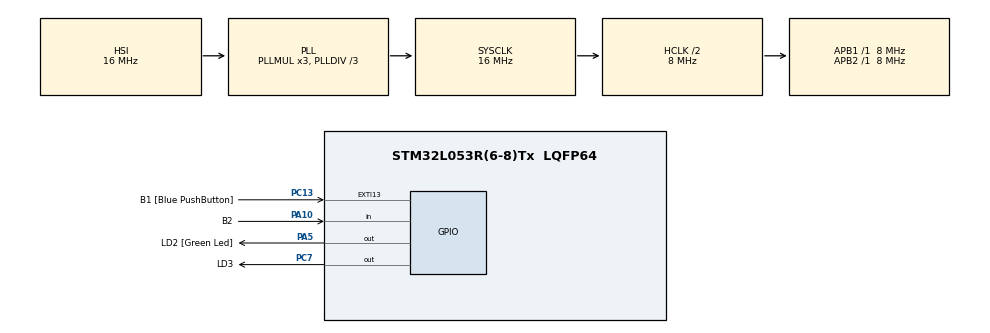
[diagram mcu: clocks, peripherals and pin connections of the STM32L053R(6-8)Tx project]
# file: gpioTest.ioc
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Mcu.Family=STM32L0
Mcu.Name=STM32L053R(6-8)Tx
Mcu.Package=LQFP64
NVIC.EXTI4_15_IRQn=true\:0\:0\:false\:false\:true\:true\:true
NVIC.TIM2_IRQn=true\:0\:0\:false\:false\:true\:true\:true
PA10.GPIO_Label=B2
PA10.Signal=GPIO_Input
PA13.GPIO_Label=TMS
PA13.Signal=SYS_SWDIO
PA14.GPIO_Label=TCK
PA14.Signal=SYS_SWCLK
PA2.GPIO_Label=USART_TX
PA2.Signal=USART2_TX
PA3.GPIO_Label=USART_RX
PA3.Signal=USART2_RX
PA5.GPIO_Label=LD2 [Green Led]
PA5.Signal=GPIO_Output
PC13.GPIO_Label=B1 [Blue PushButton]
PC13.GPIO_ModeDefaultEXTI=GPIO_MODE_IT_FALLING
PC13.Signal=GPXTI13
PC14-OSC32_IN.Signal=RCC_OSC32_IN
PC15-OSC32_OUT.Signal=RCC_OSC32_OUT
PC7.GPIO_Label=LD3
PC7.Signal=GPIO_Output
PH0-OSC_IN.Mode=HSE-External-Oscillator
PH0-OSC_IN.Signal=RCC_OSC_IN
PH1-OSC_OUT.Mode=HSE-External-Oscillator
PH1-OSC_OUT.Signal=RCC_OSC_OUT
ProjectManager.HeapSize=0x200
ProjectManager.StackSize=0x400
ProjectManager.TargetToolchain=MDK-ARM V5
RCC.AHBCLKDivider=RCC_SYSCLK_DIV2
RCC.AHBFreq_Value=8000000
RCC.APB1Freq_Value=8000000
RCC.APB1TimFreq_Value=8000000
RCC.APB2Freq_Value=8000000
RCC.APB2TimFreq_Value=8000000
RCC.HCLKFreq_Value=8000000
RCC.HSE_VALUE=8000000
RCC.HSI16_VALUE=16000000
RCC.HSI48_VALUE=48000000
RCC.HSI_VALUE=16000000
RCC.LSEState=RCC_LSE_ON
RCC.LSE_VALUE=32768
RCC.MSI_VALUE=2097000
RCC.PLLDIV=RCC_PLLDIV_3
RCC.SYSCLKFreq_VALUE=16000000
RCC.SYSCLKSource=RCC_SYSCLKSOURCE_PLLCLK
RCC.VCOOutputFreq_Value=48000000
TIM2.Period=800
TIM2.Prescaler=3999
VP_TIM2_VS_ClockSourceINT.Mode=Internal
board=NUCLEO-L053R8

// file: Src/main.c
/* USER CODE BEGIN Header */
/**
  ******************************************************************************
  * @file           : main.c
  * @brief          : Main program body
  ******************************************************************************
  * @attention
  *
  * <h2><center>&copy; Copyright (c) 2019 STMicroelectronics.
  * All rights reserved.</center></h2>
  *
  * This software component is licensed by ST under BSD 3-Clause license,
  * the "License"; You may not use this file except in compliance with the
  * License. You may obtain a copy of the License at:
  *                        opensource.org/licenses/BSD-3-Clause
  *
  ******************************************************************************
  */
/* USER CODE END Header */

#include "main.h"

TIM_HandleTypeDef htim2;

void SystemClock_Config(void);
static void MX_GPIO_Init(void);
static void MX_TIM2_Init(void);

int main(void)
{

  /* MCU Configuration--------------------------------------------------------*/

  /* Reset of all peripherals, Initializes the Flash interface and the Systick. */
  HAL_Init();

  /* Configure the system clock */
  SystemClock_Config();

  /* Initialize all configured peripherals */
  MX_GPIO_Init();
  MX_TIM2_Init();
  /* USER CODE BEGIN 2 */
	// start the timer2
	HAL_TIM_Base_Start_IT(&htim2);
  /* USER CODE END 2 */

  /* Infinite loop */
  /* USER CODE BEGIN WHILE */
  while (1)
  {
    ;
    /* USER CODE END WHILE */

    /* USER CODE BEGIN 3 */
		//HAL_GPIO_TogglePin(LD2_GPIO_Port, LD2_Pin);
		//HAL_Delay(1000);
		//if(HAL_GPIO_ReadPin(B1_GPIO_Port, B1_Pin))
			//HAL_GPIO_WritePin(LD2_GPIO_Port, LD2_Pin, GPIO_PIN_SET);
		//else
 			//HAL_GPIO_WritePin(LD2_GPIO_Port, LD2_Pin, GPIO_PIN_RESET);
  }
  /* USER CODE END 3 */
}

void SystemClock_Config(void)
{
  RCC_OscInitTypeDef RCC_OscInitStruct = {0};
  RCC_ClkInitTypeDef RCC_ClkInitStruct = {0};

  /** Configure the main internal regulator output voltage
  */
  __HAL_PWR_VOLTAGESCALING_CONFIG(PWR_REGULATOR_VOLTAGE_SCALE1);
  /** Initializes the CPU, AHB and APB busses clocks
  */
  RCC_OscInitStruct.OscillatorType = RCC_OSCILLATORTYPE_HSI;
  RCC_OscInitStruct.HSIState = RCC_HSI_ON;
  RCC_OscInitStruct.HSICalibrationValue = RCC_HSICALIBRATION_DEFAULT;
  RCC_OscInitStruct.PLL.PLLState = RCC_PLL_ON;
  RCC_OscInitStruct.PLL.PLLSource = RCC_PLLSOURCE_HSI;
  RCC_OscInitStruct.PLL.PLLMUL = RCC_PLLMUL_3;
  RCC_OscInitStruct.PLL.PLLDIV = RCC_PLLDIV_3;
  if (HAL_RCC_OscConfig(&RCC_OscInitStruct) != HAL_OK)
  {
    Error_Handler();
  }
  /** Initializes the CPU, AHB and APB busses clocks
  */
  RCC_ClkInitStruct.ClockType = RCC_CLOCKTYPE_HCLK|RCC_CLOCKTYPE_SYSCLK
                              |RCC_CLOCKTYPE_PCLK1|RCC_CLOCKTYPE_PCLK2;
  RCC_ClkInitStruct.SYSCLKSource = RCC_SYSCLKSOURCE_PLLCLK;
  RCC_ClkInitStruct.AHBCLKDivider = RCC_SYSCLK_DIV2;
  RCC_ClkInitStruct.APB1CLKDivider = RCC_HCLK_DIV1;
  RCC_ClkInitStruct.APB2CLKDivider = RCC_HCLK_DIV1;

  if (HAL_RCC_ClockConfig(&RCC_ClkInitStruct, FLASH_LATENCY_0) != HAL_OK)
  {
    Error_Handler();
  }
}

static void MX_TIM2_Init(void)
{

  TIM_ClockConfigTypeDef sClockSourceConfig = {0};
  TIM_MasterConfigTypeDef sMasterConfig = {0};

  htim2.Instance = TIM2;
  htim2.Init.Prescaler = 3999;
  htim2.Init.CounterMode = TIM_COUNTERMODE_UP;
  htim2.Init.Period = 800;
  htim2.Init.ClockDivision = TIM_CLOCKDIVISION_DIV1;
  htim2.Init.AutoReloadPreload = TIM_AUTORELOAD_PRELOAD_DISABLE;
  if (HAL_TIM_Base_Init(&htim2) != HAL_OK)
  {
    Error_Handler();
  }
  sClockSourceConfig.ClockSource = TIM_CLOCKSOURCE_INTERNAL;
  if (HAL_TIM_ConfigClockSource(&htim2, &sClockSourceConfig) != HAL_OK)
  {
    Error_Handler();
  }
  sMasterConfig.MasterOutputTrigger = TIM_TRGO_RESET;
  sMasterConfig.MasterSlaveMode = TIM_MASTERSLAVEMODE_DISABLE;
  if (HAL_TIMEx_MasterConfigSynchronization(&htim2, &sMasterConfig) != HAL_OK)
  {
    Error_Handler();
  }

}

static void MX_GPIO_Init(void)
{
  GPIO_InitTypeDef GPIO_InitStruct = {0};

  /* GPIO Ports Clock Enable */
  __HAL_RCC_GPIOC_CLK_ENABLE();
  __HAL_RCC_GPIOH_CLK_ENABLE();
  __HAL_RCC_GPIOA_CLK_ENABLE();

  /*Configure GPIO pin Output Level */
  HAL_GPIO_WritePin(LD2_GPIO_Port, LD2_Pin, GPIO_PIN_RESET);

  /*Configure GPIO pin Output Level */
  HAL_GPIO_WritePin(LD3_GPIO_Port, LD3_Pin, GPIO_PIN_RESET);

  /*Configure GPIO pin : B1_Pin */
  GPIO_InitStruct.Pin = B1_Pin;
  GPIO_InitStruct.Mode = GPIO_MODE_IT_FALLING;
  GPIO_InitStruct.Pull = GPIO_NOPULL;
  HAL_GPIO_Init(B1_GPIO_Port, &GPIO_InitStruct);

  /*Configure GPIO pins : USART_TX_Pin USART_RX_Pin */
  GPIO_InitStruct.Pin = USART_TX_Pin|USART_RX_Pin;
  GPIO_InitStruct.Mode = GPIO_MODE_AF_PP;
  GPIO_InitStruct.Pull = GPIO_NOPULL;
  GPIO_InitStruct.Speed = GPIO_SPEED_FREQ_VERY_HIGH;
  GPIO_InitStruct.Alternate = GPIO_AF4_USART2;
  HAL_GPIO_Init(GPIOA, &GPIO_InitStruct);

  /*Configure GPIO pin : LD2_Pin */
  GPIO_InitStruct.Pin = LD2_Pin;
  GPIO_InitStruct.Mode = GPIO_MODE_OUTPUT_PP;
  GPIO_InitStruct.Pull = GPIO_NOPULL;
  GPIO_InitStruct.Speed = GPIO_SPEED_FREQ_LOW;
  HAL_GPIO_Init(LD2_GPIO_Port, &GPIO_InitStruct);

  /*Configure GPIO pin : LD3_Pin */
  GPIO_InitStruct.Pin = LD3_Pin;
  GPIO_InitStruct.Mode = GPIO_MODE_OUTPUT_PP;
  GPIO_InitStruct.Pull = GPIO_NOPULL;
  GPIO_InitStruct.Speed = GPIO_SPEED_FREQ_LOW;
  HAL_GPIO_Init(LD3_GPIO_Port, &GPIO_InitStruct);

  /*Configure GPIO pin : B2_Pin */
  GPIO_InitStruct.Pin = B2_Pin;
  GPIO_InitStruct.Mode = GPIO_MODE_INPUT;
  GPIO_InitStruct.Pull = GPIO_NOPULL;
  HAL_GPIO_Init(B2_GPIO_Port, &GPIO_InitStruct);

  /* EXTI interrupt init*/
  HAL_NVIC_SetPriority(EXTI4_15_IRQn, 0, 0);
  HAL_NVIC_EnableIRQ(EXTI4_15_IRQn);

}

/* USER CODE BEGIN 4 */
/**
  * @brief EXTI line detection callbacks
  * @param GPIO_Pin: Specifies the pins connected EXTI line
  * @retval None
  */
/*
void HAL_GPIO_EXTI_Callback(uint16_t GPIO_Pin)
{
  if(GPIO_Pin == B1_Pin)
  {
    //Toggle LED1
		HAL_GPIO_TogglePin(LD2_GPIO_Port, LD2_Pin);
  }
	else
		__NOP();
}

*/

/**
  * @brief Timer interrupt callbacks
  * @param Timer2
  * @retval None
  */
void HAL_TIM_PeriodElapsedCallback(TIM_HandleTypeDef *htim)

{
  if(htim->Instance == TIM2)
  {
    // Toggle LED1
		HAL_GPIO_TogglePin(LD2_GPIO_Port, LD2_Pin);
  }
	else
		__NOP();
}

/* USER CODE END 4 */

void Error_Handler(void)
{
}

/************************ (C) COPYRIGHT STMicroelectronics *****END OF FILE****/
